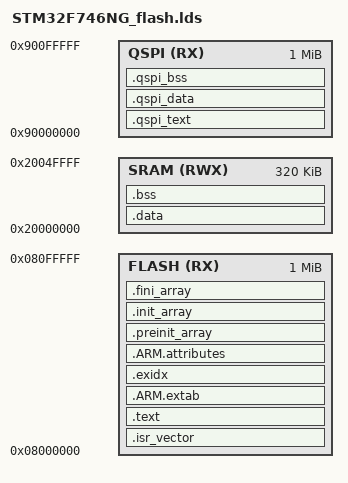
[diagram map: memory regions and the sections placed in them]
/* Generated by LinkerScriptGenerator [http://visualgdb.com/tools/LinkerScriptGenerator]
 * Target: STM32F746NG
 * The file is provided under the BSD license.
 */

ENTRY(Reset_Handler)

MEMORY
{
	FLASH (RX) : ORIGIN = 0x08000000, LENGTH = 1M
	SRAM (RWX) : ORIGIN = 0x20000000, LENGTH = 320K
	/* --- begin generated external memories -- */
	QSPI (RX) : ORIGIN = 0x90000000, LENGTH = 1024K
	/* --- end generated external memories -- */
}

_estack = 0x20050000;

SECTIONS
{
	.isr_vector :
	{
		. = ALIGN(4);
		KEEP(*(.isr_vector))
		. = ALIGN(4);
	} > FLASH

	.text :
	{
		. = ALIGN(4);
		_stext = .;

		*(.text)
		*(.text*)
		*(.rodata)
		*(.rodata*)
		*(.glue_7)
		*(.glue_7t)
		KEEP(*(.init))
		KEEP(*(.fini))
		. = ALIGN(4);
		_etext = .;

	} > FLASH

	.ARM.extab :
	{
		. = ALIGN(4);
		*(.ARM.extab)
		*(.gnu.linkonce.armextab.*)
		. = ALIGN(4);
	} > FLASH

	.exidx :
	{
		. = ALIGN(4);
		PROVIDE(__exidx_start = .);
		*(.ARM.exidx*)
		. = ALIGN(4);
		PROVIDE(__exidx_end = .);
	} > FLASH

	.ARM.attributes :
	{
		*(.ARM.attributes)
	} > FLASH

	.preinit_array :
	{
		PROVIDE(__preinit_array_start = .);
		KEEP(*(.preinit_array*))
		PROVIDE(__preinit_array_end = .);
	} > FLASH

	.init_array :
	{
		PROVIDE(__init_array_start = .);
		KEEP(*(SORT(.init_array.*)))
		KEEP(*(.init_array*))
		PROVIDE(__init_array_end = .);
	} > FLASH

	.fini_array :
	{
		PROVIDE(__fini_array_start = .);
		KEEP(*(.fini_array*))
		KEEP(*(SORT(.fini_array.*)))
		PROVIDE(__fini_array_end = .);
	} > FLASH

	. = ALIGN(4);
	_sidata = .;

	.data : AT(_sidata)
	{
		. = ALIGN(4);
		_sdata = .;

		PROVIDE(__data_start__ = _sdata);
		*(.data)
		*(.data*)
		. = ALIGN(4);
		_edata = .;

		PROVIDE(__data_end__ = _edata);
	} > SRAM

	.bss :
	{
		. = ALIGN(4);
		_sbss = .;

		PROVIDE(__bss_start__ = _sbss);
		*(.bss)
		*(.bss*)
		*(COMMON)
		. = ALIGN(4);
		_ebss = .;

		PROVIDE(__bss_end__ = _ebss);
	} > SRAM
	/* --- begin generated external memory sections -- */
	.qspi_text :
	{
		. = ALIGN(4);
		_sqspi_text = .;

		PROVIDE(__qspi_text_start = _sqspi_text);
		*(.qspi_text)
		*(.qspi_text*)
		. = ALIGN(4);
		_eqspi_text = .;

		PROVIDE(__qspi_text_end = _eqspi_text);
	} > QSPI

	.qspi_data :
	{
		. = ALIGN(4);
		_sqspi_data = .;

		PROVIDE(__qspi_data_start = _sqspi_data);
		*(.qspi_data)
		*(.qspi_data*)
		. = ALIGN(4);
		_eqspi_data = .;

		PROVIDE(__qspi_data_end = _eqspi_data);
	} > QSPI

	.qspi_bss (NOLOAD) :
	{
		. = ALIGN(4);
		_sqspi_bss = .;

		PROVIDE(__qspi_bss_start = _sqspi_bss);
		*(.qspi_bss)
		*(.qspi_bss*)
		. = ALIGN(4);
		_eqspi_bss = .;

		PROVIDE(__qspi_bss_end = _eqspi_bss);
	} > QSPI

	/* --- end generated external memory sections -- */


	PROVIDE(end = .);

}

